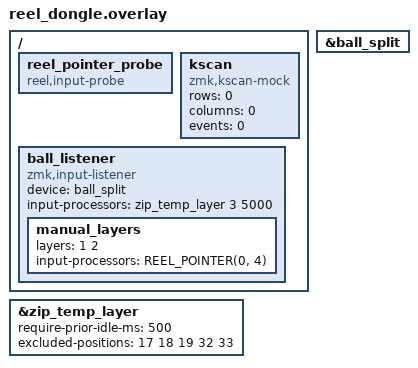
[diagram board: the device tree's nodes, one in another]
#include "reel.dtsi"
#include <input/processors.dtsi>
#include <input/processors/spike_filter.dtsi>
#include <input/processors/response_curve.dtsi>
#include <dt-bindings/zmk/input_transform.h>

&ball_split { status = "okay"; };

&zip_temp_layer {
    require-prior-idle-ms = <500>;
    // Zero-based keymap positions: L/K/J (MB2/3/1), then MB5/4.
    excluded-positions = <17 18 19 32 33>;
};

// Base sensitivity without the response curve: 1600 sensor CPI * 3/8 = 600 CPI.
// Trace raw -> LPF -> RC -> scaled output; L1/L2 use RC0 for live comparison.
#define REEL_POINTER(curve, probe_offset) <&reel_pointer_probe (probe_offset)>, <&zip_spike_filter 3>, <&reel_pointer_probe (probe_offset + 1)>, <&zip_response_curve curve>, <&reel_pointer_probe (probe_offset + 2)>, <&zip_xy_transform (INPUT_TRANSFORM_XY_SWAP | INPUT_TRANSFORM_Y_INVERT)>, <&zip_xy_scaler 3 8>, <&reel_pointer_probe (probe_offset + 3)>

/ {
    reel_pointer_probe: reel_pointer_probe {
        compatible = "reel,input-probe";
        #input-processor-cells = <1>;
    };

    kscan: kscan {
        compatible = "zmk,kscan-mock";
        rows = <0>;
        columns = <0>;
        events = <0>;
    };

    ball_listener {
        compatible = "zmk,input-listener";
        device = <&ball_split>;
        // Dominant directions of the RMK calibration: (raw Y, -raw X).
        input-processors = REEL_POINTER(3, 0), <&zip_temp_layer 3 5000>;

        manual_layers {
            layers = <1 2>;
            input-processors = REEL_POINTER(0, 4);
        };
    };
};
